VERSION ""

NS_ :

BS_:

BU_: MS6_Logger_CAN_Bus_1 IM_GCM IZZE_BRK_IR IZZE_RL IZZE_FL IZZE_RR IZZE_FR IMU WL_IZZE_RIGHT WL_IZZE_LEFT S350

BO_ 1956 BRK_IR_TEMP_STATUS: 8 Vector__XXX
 SG_ BRK_IR_Internal_Temperature : 7|16@0+ (0.1,-100) [0|65535] "C" Vector__XXX

BO_ 256 IM_GCM_MS6_Gear: 8 IM_GCM
 SG_ GCM_Gear_Bosch : 0|8@1+ (0.5,-1.5) [0|0] "" Vector__XXX

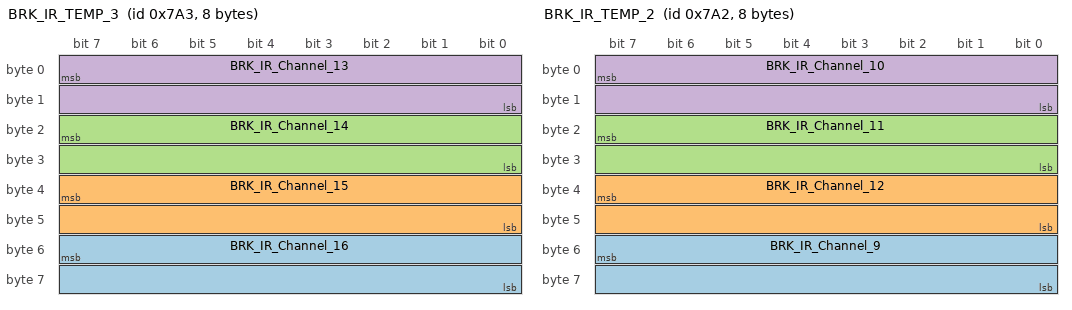
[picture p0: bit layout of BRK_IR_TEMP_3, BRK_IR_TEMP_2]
BO_ 1955 BRK_IR_TEMP_3: 8 IZZE_BRK_IR
 SG_ BRK_IR_Channel_16 : 55|16@0+ (0.1,-100) [0|65535] "C" Vector__XXX
 SG_ BRK_IR_Channel_15 : 39|16@0+ (0.1,-100) [0|65535] "C" Vector__XXX
 SG_ BRK_IR_Channel_14 : 23|16@0+ (0.1,-100) [0|65535] "C" Vector__XXX
 SG_ BRK_IR_Channel_13 : 7|16@0+ (0.1,-100) [0|65535] "C" Vector__XXX

BO_ 1954 BRK_IR_TEMP_2: 8 IZZE_BRK_IR
 SG_ BRK_IR_Channel_9 : 55|16@0+ (0.1,-100) [0|65535] "C" Vector__XXX
 SG_ BRK_IR_Channel_12 : 39|16@0+ (0.1,-100) [0|65535] "C" Vector__XXX
 SG_ BRK_IR_Channel_11 : 23|16@0+ (0.1,-100) [0|65535] "C" Vector__XXX
 SG_ BRK_IR_Channel_10 : 7|16@0+ (0.1,-100) [0|65535] "C" Vector__XXX

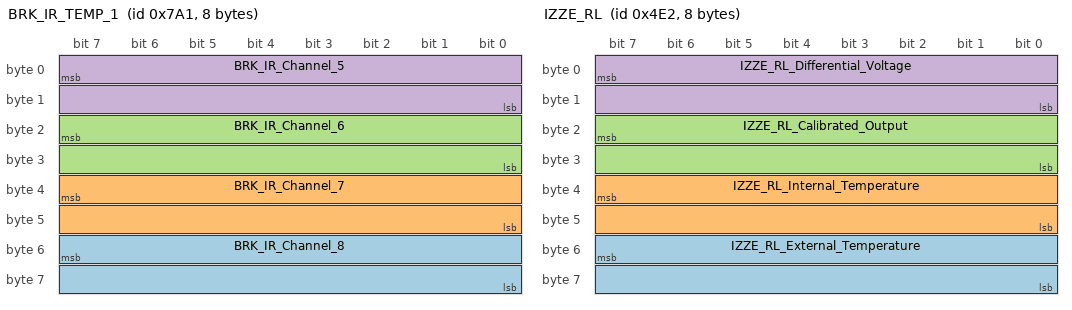
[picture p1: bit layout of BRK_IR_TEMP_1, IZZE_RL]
BO_ 1953 BRK_IR_TEMP_1: 8 IZZE_BRK_IR
 SG_ BRK_IR_Channel_8 : 55|16@0+ (0.1,-100) [0|65535] "C" Vector__XXX
 SG_ BRK_IR_Channel_7 : 39|16@0+ (0.1,-100) [0|65535] "C" Vector__XXX
 SG_ BRK_IR_Channel_6 : 23|16@0+ (0.1,-100) [0|65535] "C" Vector__XXX
 SG_ BRK_IR_Channel_5 : 7|16@0+ (0.1,-100) [0|65535] "C" Vector__XXX

BO_ 1552 IM_GCM_MS6_Shift: 8 IM_GCM
 SG_ GCM_Upshift_Bosch : 1|1@1+ (1,0) [0|0] "" Vector__XXX
 SG_ GCM_Downshift_Bosch : 0|1@1+ (1,0) [0|0] "" Vector__XXX

BO_ 1250 IZZE_RL: 8 IZZE_RL
 SG_ IZZE_RL_External_Temperature : 55|16@0- (0.1,0) [0|0] "C" Vector__XXX
 SG_ IZZE_RL_Internal_Temperature : 39|16@0- (0.1,0) [0|0] "C" Vector__XXX
 SG_ IZZE_RL_Calibrated_Output : 23|16@0- (0.1,0) [0|0] "F" Vector__XXX
 SG_ IZZE_RL_Differential_Voltage : 7|16@0- (1,0) [0|0] "µV" Vector__XXX

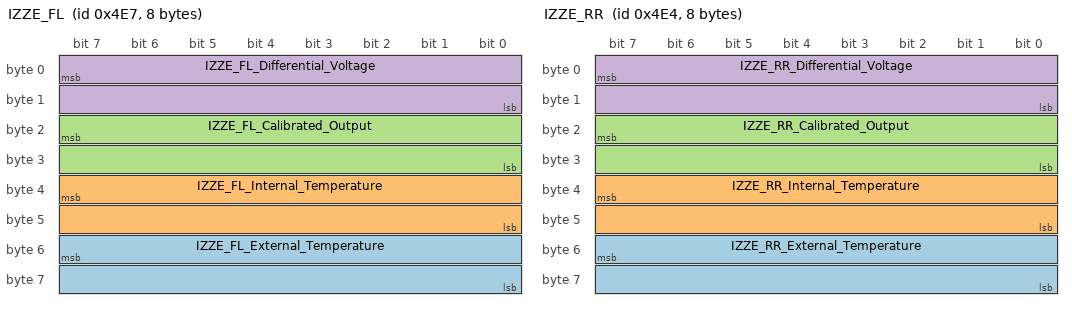
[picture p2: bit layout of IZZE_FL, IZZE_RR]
BO_ 1255 IZZE_FL: 8 IZZE_FL
 SG_ IZZE_FL_External_Temperature : 55|16@0- (0.1,0) [0|0] "C" Vector__XXX
 SG_ IZZE_FL_Internal_Temperature : 39|16@0- (0.1,0) [0|0] "C" Vector__XXX
 SG_ IZZE_FL_Calibrated_Output : 23|16@0- (0.1,0) [0|0] "F" Vector__XXX
 SG_ IZZE_FL_Differential_Voltage : 7|16@0- (1,0) [0|0] "µV" Vector__XXX

BO_ 1252 IZZE_RR: 8 IZZE_RR
 SG_ IZZE_RR_External_Temperature : 55|16@0- (0.1,0) [0|0] "C" Vector__XXX
 SG_ IZZE_RR_Internal_Temperature : 39|16@0- (0.1,0) [0|0] "C" Vector__XXX
 SG_ IZZE_RR_Calibrated_Output : 23|16@0- (0.1,0) [0|0] "F" Vector__XXX
 SG_ IZZE_RR_Differential_Voltage : 7|16@0- (1,0) [0|0] "µV" Vector__XXX

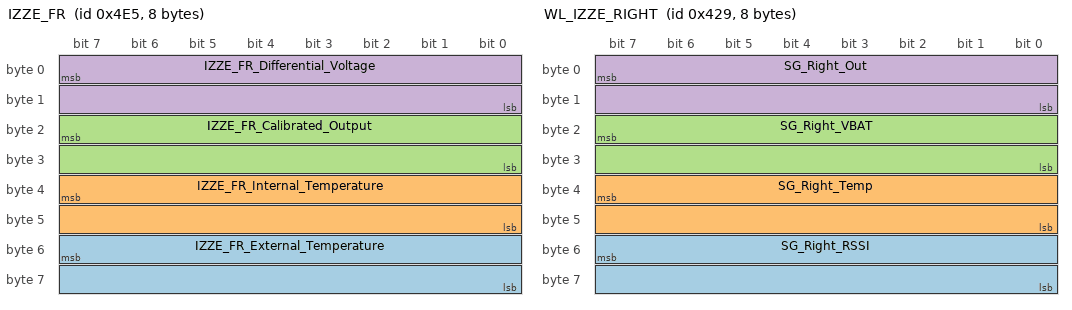
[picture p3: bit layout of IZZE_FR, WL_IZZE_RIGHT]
BO_ 1253 IZZE_FR: 8 IZZE_FR
 SG_ IZZE_FR_External_Temperature : 55|16@0- (0.1,0) [0|0] "C" Vector__XXX
 SG_ IZZE_FR_Internal_Temperature : 39|16@0- (0.1,0) [0|0] "C" Vector__XXX
 SG_ IZZE_FR_Calibrated_Output : 23|16@0- (0.1,0) [0|0] "F" Vector__XXX
 SG_ IZZE_FR_Differential_Voltage : 7|16@0- (1,0) [0|0] "µV" Vector__XXX

BO_ 380 IMU_2: 8 IMU
 SG_ IMU_Z_Accel : 32|16@1+ (0.0001274,-4.1746432) [0|0] "g" Vector__XXX

BO_ 1065 WL_IZZE_RIGHT: 8 WL_IZZE_RIGHT
 SG_ SG_Right_RSSI : 55|16@0- (1,0) [0|0] "dBm" Vector__XXX
 SG_ SG_Right_Temp : 39|16@0- (0.1,0) [0|0] "C" Vector__XXX
 SG_ SG_Right_VBAT : 23|16@0- (0.001,0) [0|0] "V" Vector__XXX
 SG_ SG_Right_Out : 7|16@0- (-1,0) [0|0] "uV" Vector__XXX

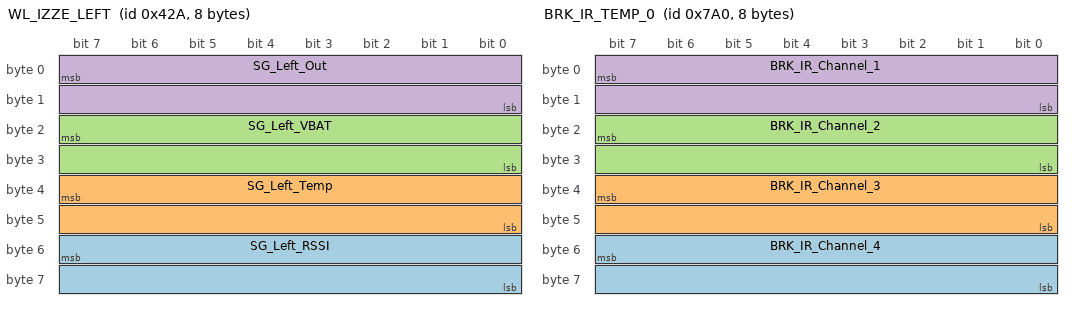
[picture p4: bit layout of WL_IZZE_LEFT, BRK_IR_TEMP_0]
BO_ 1066 WL_IZZE_LEFT: 8 WL_IZZE_LEFT
 SG_ SG_Left_RSSI : 55|16@0- (1,0) [0|0] "dBm" Vector__XXX
 SG_ SG_Left_Temp : 39|16@0- (0.1,0) [0|0] "C" Vector__XXX
 SG_ SG_Left_VBAT : 23|16@0- (0.001,0) [0|0] "V" Vector__XXX
 SG_ SG_Left_Out : 7|16@0- (1,0) [0|0] "uV" Vector__XXX

BO_ 1952 BRK_IR_TEMP_0: 8 IZZE_BRK_IR
 SG_ BRK_IR_Channel_4 : 55|16@0+ (0.1,-100) [0|65535] "C" Vector__XXX
 SG_ BRK_IR_Channel_3 : 39|16@0+ (0.1,-100) [0|65535] "C" Vector__XXX
 SG_ BRK_IR_Channel_2 : 23|16@0+ (0.1,-100) [0|65535] "C" Vector__XXX
 SG_ BRK_IR_Channel_1 : 7|16@0+ (0.1,-100) [0|65535] "C" Vector__XXX

BO_ 376 IMU_1: 8 IMU
 SG_ IMU_X_Accel : 32|16@1+ (0.0001274,-4.1746432) [0|0] "g" Vector__XXX
 SG_ IMU_Roll_Rate : 0|16@1+ (0.005,-163.84) [0|0] "deg/s/s" Vector__XXX

BO_ 372 IMU_0: 8 IMU
 SG_ IMU_Y_Accel : 32|16@1+ (0.0001274,-4.1746432) [0|0] "g" Vector__XXX
 SG_ IMU_Yaw_Rate : 0|16@1+ (0.005,-163.84) [0|0] "deg/s" Vector__XXX

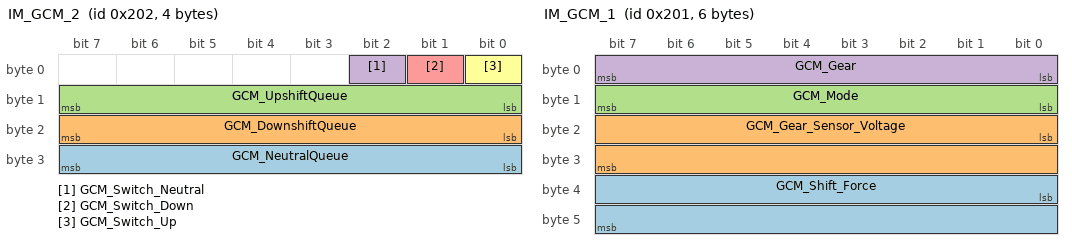
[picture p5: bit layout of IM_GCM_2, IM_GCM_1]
BO_ 514 IM_GCM_2: 4 IM_GCM
 SG_ GCM_NeutralQueue : 24|8@1+ (1,0) [0|0] "" Vector__XXX
 SG_ GCM_DownshiftQueue : 16|8@1+ (1,0) [0|0] "" Vector__XXX
 SG_ GCM_UpshiftQueue : 8|8@1+ (1,0) [0|0] "" Vector__XXX
 SG_ GCM_Switch_Neutral : 2|1@1+ (1,0) [0|0] "" Vector__XXX
 SG_ GCM_Switch_Down : 1|1@1+ (1,0) [0|0] "" Vector__XXX
 SG_ GCM_Switch_Up : 0|1@1+ (1,0) [0|0] "" Vector__XXX

BO_ 513 IM_GCM_1: 6 IM_GCM
 SG_ GCM_Shift_Force : 32|16@1- (0.01,0) [0|0] "N" Vector__XXX
 SG_ GCM_Gear_Sensor_Voltage : 16|16@1+ (0.0001,0) [0|0] "V" Vector__XXX
 SG_ GCM_Mode : 8|8@1+ (1,0) [0|0] "" Vector__XXX
 SG_ GCM_Gear : 0|8@1+ (1,0) [0|0] "" Vector__XXX

BO_ 15 IM_ERR: 4 IM_GCM
 SG_ ERR_Code : 16|16@1+ (1,0) [0|0] "" Vector__XXX
 SG_ ERR_Origin_Node : 0|16@1+ (1,0) [0|0] "" Vector__XXX

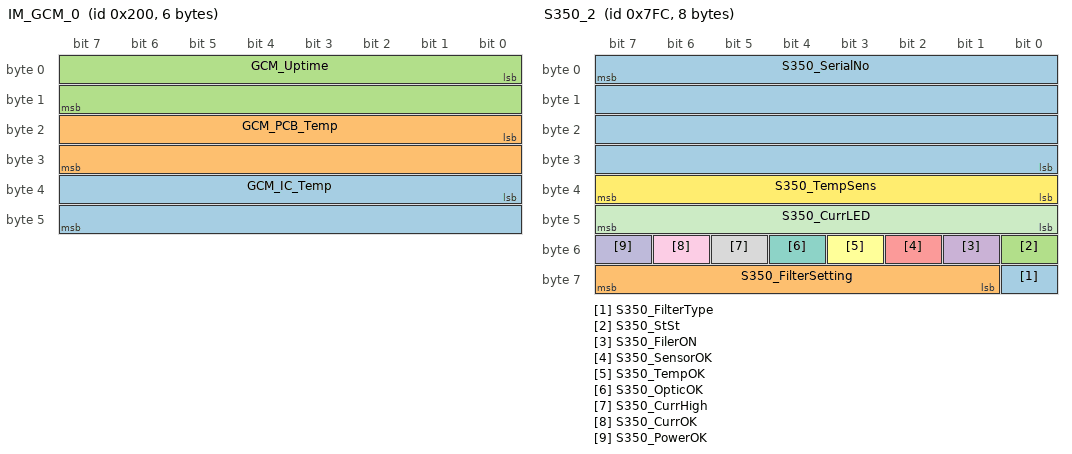
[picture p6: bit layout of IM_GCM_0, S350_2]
BO_ 512 IM_GCM_0: 6 IM_GCM
 SG_ GCM_IC_Temp : 32|16@1- (0.005,0) [0|0] "C" Vector__XXX
 SG_ GCM_PCB_Temp : 16|16@1- (0.005,0) [0|0] "C" Vector__XXX
 SG_ GCM_Uptime : 0|16@1+ (1,0) [0|0] "s" Vector__XXX

BO_ 2044 S350_2: 8 S350
 SG_ S350_FilterType : 56|1@0+ (1,0) [0|1] ""  S350
 SG_ S350_FilterSetting : 63|7@0+ (1,0) [0|127] ""  S350
 SG_ S350_StSt : 48|1@0+ (1,0) [0|1] ""  S350
 SG_ S350_FilerON : 49|1@0+ (1,0) [0|1] ""  S350
 SG_ S350_SensorOK : 50|1@0+ (1,0) [0|1] ""  S350
 SG_ S350_TempOK : 51|1@0+ (1,0) [0|1] ""  S350
 SG_ S350_OpticOK : 52|1@0+ (1,0) [0|1] ""  S350
 SG_ S350_CurrHigh : 53|1@0+ (1,0) [0|1] ""  S350
 SG_ S350_CurrOK : 54|1@0+ (1,0) [0|1] ""  S350
 SG_ S350_PowerOK : 55|1@0+ (1,0) [0|1] ""  S350
 SG_ S350_CurrLED : 47|8@0+ (0.01,0) [0|2.55] "A"  S350
 SG_ S350_TempSens : 39|8@0- (1,0) [-128|127] "°C"  S350
 SG_ S350_SerialNo : 7|32@0+ (1,0) [0|4294970000] ""  S350

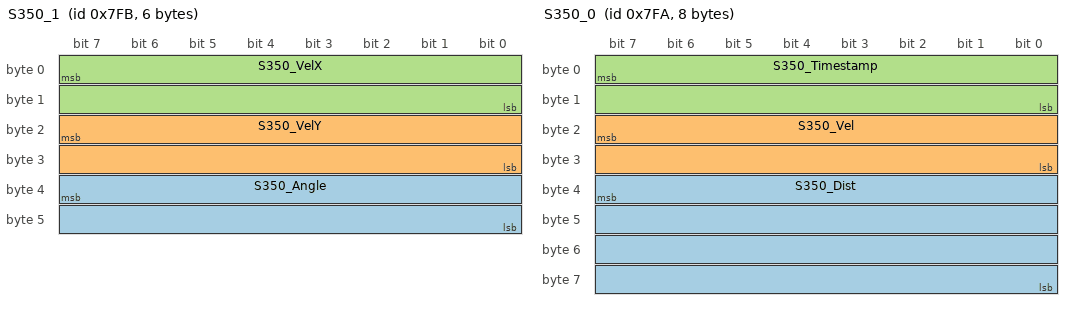
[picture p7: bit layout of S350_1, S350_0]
BO_ 2043 S350_1: 6 S350
 SG_ S350_Angle : 39|16@0- (0.01,0) [-45|45] "°"  S350
 SG_ S350_VelY : 23|16@0- (0.036,0) [-100|100] "km/h"  S350
 SG_ S350_VelX : 7|16@0+ (0.036,0) [0|400] "km/h"  S350

BO_ 2042 S350_0: 8 S350
 SG_ S350_Dist : 39|32@0+ (0.001,0) [0|4294970] "m"  S350
 SG_ S350_Vel : 23|16@0+ (0.036,0) [0|400] "km/h"  S350
 SG_ S350_Timestamp : 7|16@0+ (1,0) [0|65535] ""  S350

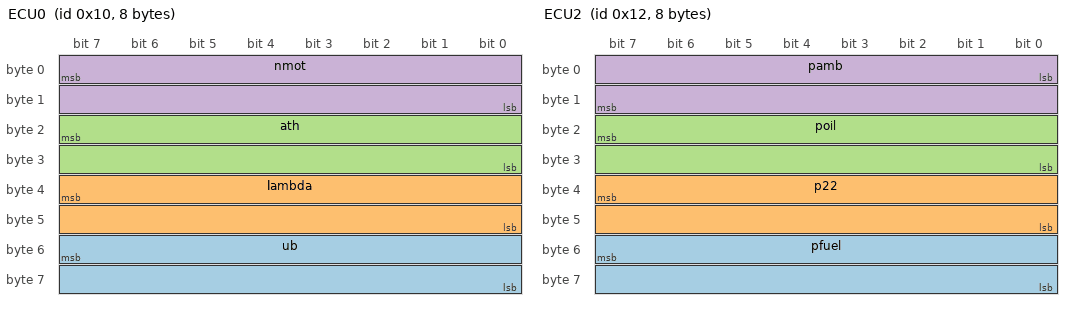
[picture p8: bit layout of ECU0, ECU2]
BO_ 16 ECU0: 8 MS6_Logger_CAN_Bus_1
 SG_ ub : 55|16@0- (0.01,0) [0|25.5] "V" Vector__XXX
 SG_ lambda : 39|16@0- (0.001,0) [0|5] "" Vector__XXX
 SG_ ath : 23|16@0- (0.1,0) [0|110] "%" Vector__XXX
 SG_ nmot : 7|16@0- (1,0) [0|20000] "rpm" Vector__XXX

BO_ 18 ECU2: 8 MS6_Logger_CAN_Bus_1
 SG_ pfuel : 55|16@0- (0.001,0) [0|10] "bar" Vector__XXX
 SG_ p22 : 39|16@0- (1,0) [0|5000] "mbar" Vector__XXX
 SG_ poil : 23|16@0- (0.001,0) [0|10] "bar" Vector__XXX
 SG_ pamb : 0|16@1+ (0.1,0) [0|2000] "mbar" Vector__XXX

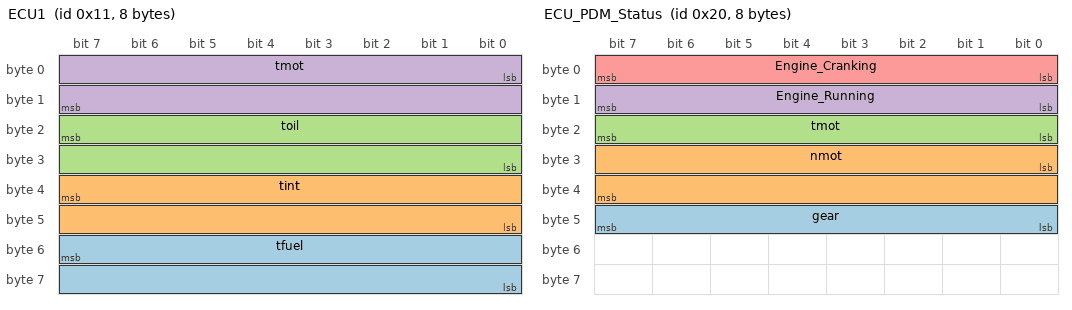
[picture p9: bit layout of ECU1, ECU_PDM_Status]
BO_ 17 ECU1: 8 MS6_Logger_CAN_Bus_1
 SG_ tfuel : 55|16@0+ (0.1,0) [10|80] "°C" Vector__XXX
 SG_ tint : 39|16@0- (0.1,0) [10|60] "°C" Vector__XXX
 SG_ toil : 23|16@0- (0.1,0) [60|150] "°C" Vector__XXX
 SG_ tmot : 0|16@1- (0.1,0) [40|120] "°C" Vector__XXX

BO_ 32 ECU_PDM_Status: 8 MS6_Logger_CAN_Bus_1
 SG_ gear : 40|8@1- (1,0) [-1|12] "" Vector__XXX
 SG_ nmot : 24|16@1+ (1,0) [0|20000] "rpm" Vector__XXX
 SG_ tmot : 16|8@1+ (1,0) [40|120] "°C" Vector__XXX
 SG_ Engine_Running : 8|8@1+ (1,0) [0|1] "" Vector__XXX
 SG_ Engine_Cranking : 0|8@1+ (1,0) [0|1] "" Vector__XXX

CM_ BO_ 1956 "Brake IR channels 13-16";
CM_ BO_ 1955 "Brake IR channels 13-16";
CM_ BO_ 1954 "Brake IR channels 9-12";
CM_ BO_ 1953 "Brake IR channels 5-8";
CM_ BO_ 1552 "Upshift/downshift ignition cut triggers for the MS6";
CM_ BO_ 1250 "Rear left IZZE - raw voltage, calibrated output, temperatures";
CM_ BO_ 1255 "Front left IZZE - raw voltage, calibrated output, temperatures";
CM_ BO_ 1252 "Rear right IZZE - raw voltage, calibrated output, temperatures";
CM_ BO_ 1253 "Front right IZZE - raw voltage, calibrated output, temperatures";
CM_ BO_ 380 "Z accel";
CM_ BO_ 1065 "Right wireless IZZE - Output, Battery, Temperature, RSSI";
CM_ BO_ 1066 "Left wireless IZZE - Output, Battery, Temperature, RSSI";
CM_ BO_ 1952 "Brake IR channels 1-4";
CM_ BO_ 376 "Roll rate, X accel";
CM_ BO_ 372 "Yaw rate, Y accel";
CM_ BO_ 514 "Paddles, Shift Queues";
CM_ BO_ 513 "Gear, Gear Sensor Voltage, Mode, Shift force";
CM_ BO_ 15 "Error flags for IM boards";
CM_ BO_ 512 "Uptime, Temperatures";
CM_ BO_ 2044 "Device status";
CM_ BO_ 2043 "Velocity X, Velocity Y, Slip angle";
CM_ BO_ 2042 "Timestamp, velocity, distance";
CM_ BO_ 16 "RPM, Throttle Position, Lambda, VBAT";
CM_ SG_ 16 ub "battery voltage";
CM_ SG_ 16 lambda "Lambda actual value";
CM_ SG_ 16 ath "throttle position";
CM_ SG_ 16 nmot "engine speed";
CM_ BO_ 18 "Ambient Pressure, Oil Pressure, Manifold Pressure, Fuel Pressure";
CM_ SG_ 18 pfuel "fuel pressure";
CM_ SG_ 18 p22 "intake manifold pressure downstream throttle";
CM_ SG_ 18 poil "oil pressure";
CM_ SG_ 18 pamb "ambient pressure";
CM_ BO_ 17 "Coolant Temp, Oil Temp, Manifold Temp, Fuel Temp";
CM_ SG_ 17 tfuel "fuel temperature";
CM_ SG_ 17 tint "intake air temperature";
CM_ SG_ 17 toil "oil temperature";
CM_ SG_ 17 tmot "engine temperature";
CM_ BO_ 32 "Engine_Cranking, Engine_Running, tmot, nmot, gear";
CM_ SG_ 32 gear "selected gear";
CM_ SG_ 32 nmot "engine speed";
CM_ SG_ 32 tmot "engine temperature";
CM_ SG_ 32 Engine_Running "Returns true, if (nmot > 0)";
CM_ SG_ 32 Engine_Cranking "Returns true, if (1 <= nmot <= 550)";
VAL_ 2044 S350_FilterType 1 "FIR" 0 "MAVG" ;
VAL_ 2044 S350_FilerON 1 "ON" 0 "OFF" ;
